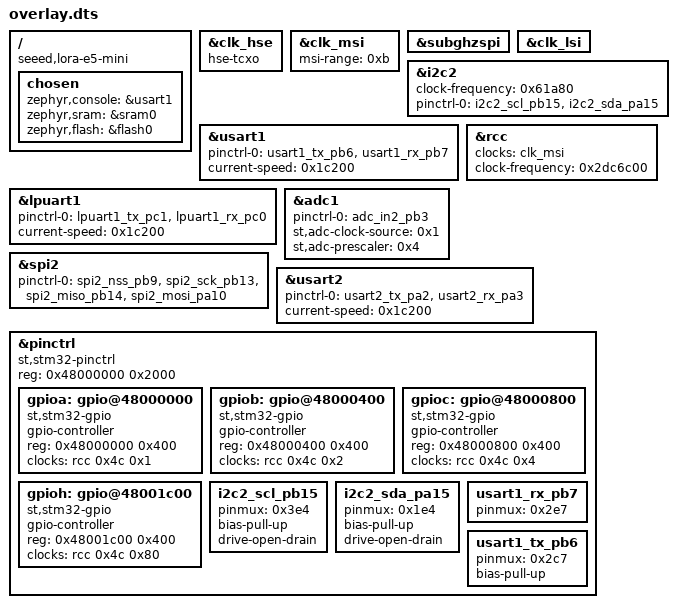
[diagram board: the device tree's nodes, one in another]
/ {
	compatible = "seeed,lora-e5-mini";
	chosen {
		zephyr,console = &usart1;
		zephyr,sram = &sram0;
		zephyr,flash = &flash0;
	};
};
&clk_hse{
	hse-tcxo;
};
&clk_msi{
	msi-range = < 0xb >;
	status = "okay";
};
&subghzspi{
	status = "okay";
};
&clk_lsi{
	status = "okay";
};
&i2c2{
	clock-frequency = < 0x61a80 >;
	status = "okay";
	pinctrl-0 = < &i2c2_scl_pb15 &i2c2_sda_pa15 >;
	pinctrl-names = "default";
};
&usart1{
	status = "okay";
	pinctrl-0 = < &usart1_tx_pb6 &usart1_rx_pb7 >;
	pinctrl-names = "default";
	current-speed = < 0x1c200 >;
};
&rcc{
	clocks = < &clk_msi >;
	clock-frequency = < 0x2dc6c00 >;
};
&lpuart1{
	status = "okay";
	pinctrl-0 = < &lpuart1_tx_pc1 &lpuart1_rx_pc0 >;
	pinctrl-names = "default";
	current-speed = < 0x1c200 >;
};
&adc1{
	status = "okay";
	pinctrl-0 = < &adc_in2_pb3 >;
	pinctrl-names = "default";
	st,adc-clock-source = < 0x1 >;
	st,adc-prescaler = < 0x4 >;
};
&spi2{
	status = "okay";
	pinctrl-0 = < &spi2_nss_pb9 &spi2_sck_pb13 &spi2_miso_pb14 &spi2_mosi_pa10 >;
	pinctrl-names = "default";
};
&usart2{
	status = "okay";
	pinctrl-0 = < &usart2_tx_pa2 &usart2_rx_pa3 >;
	pinctrl-names = "default";
	current-speed = < 0x1c200 >;
};
&pinctrl{
	compatible = "st,stm32-pinctrl";
	#address-cells = < 0x1 >;
	#size-cells = < 0x1 >;
	reg = < 0x48000000 0x2000 >;
	gpioa: gpio@48000000 {
		compatible = "st,stm32-gpio";
		gpio-controller;
		#gpio-cells = < 0x2 >;
		reg = < 0x48000000 0x400 >;
		clocks = < &rcc 0x4c 0x1 >;
	};
	gpiob: gpio@48000400 {
		compatible = "st,stm32-gpio";
		gpio-controller;
		#gpio-cells = < 0x2 >;
		reg = < 0x48000400 0x400 >;
		clocks = < &rcc 0x4c 0x2 >;
	};
	gpioc: gpio@48000800 {
		compatible = "st,stm32-gpio";
		gpio-controller;
		#gpio-cells = < 0x2 >;
		reg = < 0x48000800 0x400 >;
		clocks = < &rcc 0x4c 0x4 >;
	};
	gpioh: gpio@48001c00 {
		compatible = "st,stm32-gpio";
		gpio-controller;
		#gpio-cells = < 0x2 >;
		reg = < 0x48001c00 0x400 >;
		clocks = < &rcc 0x4c 0x80 >;
	};
	i2c2_scl_pb15: i2c2_scl_pb15 {
		pinmux = < 0x3e4 >;
		bias-pull-up;
		drive-open-drain;
	};
	i2c2_sda_pa15: i2c2_sda_pa15 {
		pinmux = < 0x1e4 >;
		bias-pull-up;
		drive-open-drain;
	};
	usart1_rx_pb7: usart1_rx_pb7 {
		pinmux = < 0x2e7 >;
	};
	usart1_tx_pb6: usart1_tx_pb6 {
		pinmux = < 0x2c7 >;
		bias-pull-up;
	};
};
